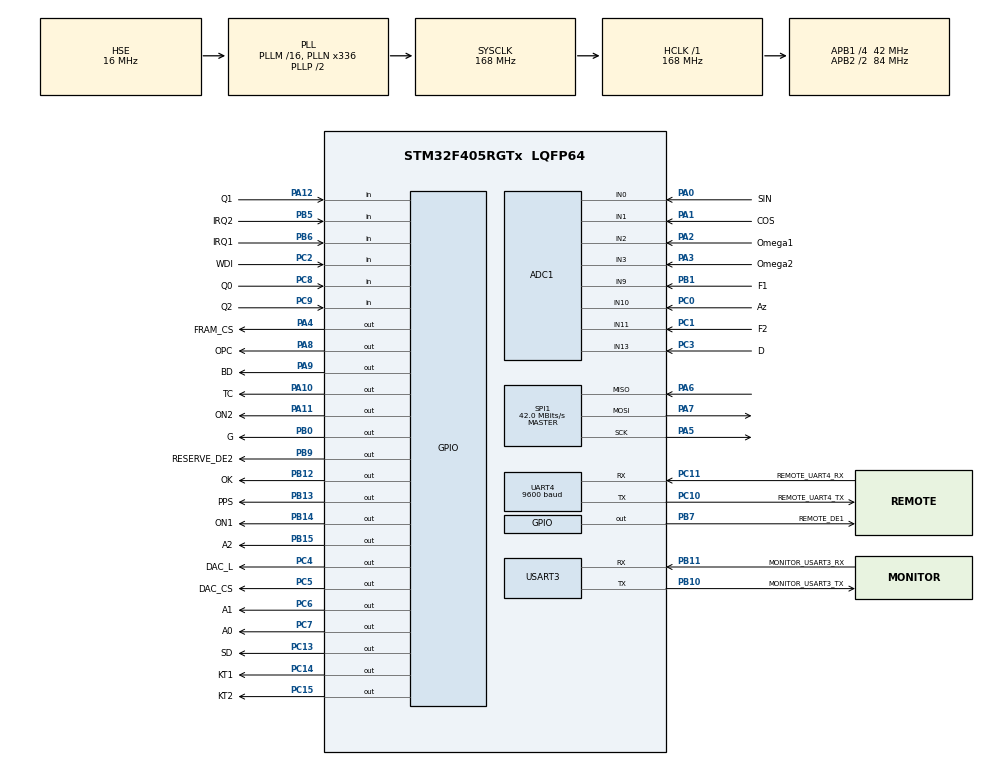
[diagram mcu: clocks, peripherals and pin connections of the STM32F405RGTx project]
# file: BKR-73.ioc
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ADC1.Channel-0\#ChannelRegularConversion=ADC_CHANNEL_0
ADC1.Channel-2\#ChannelRegularConversion=ADC_CHANNEL_1
ADC1.Channel-3\#ChannelRegularConversion=ADC_CHANNEL_2
ADC1.Channel-4\#ChannelRegularConversion=ADC_CHANNEL_3
ADC1.Channel-5\#ChannelRegularConversion=ADC_CHANNEL_9
ADC1.Channel-6\#ChannelRegularConversion=ADC_CHANNEL_10
ADC1.Channel-7\#ChannelRegularConversion=ADC_CHANNEL_11
ADC1.Channel-8\#ChannelRegularConversion=ADC_CHANNEL_13
ADC1.ClockPrescaler=ADC_CLOCK_SYNC_PCLK_DIV8
ADC1.ContinuousConvMode=ENABLE
ADC1.DMAContinuousRequests=ENABLE
ADC1.EOCSelection=ADC_EOC_SEQ_CONV
ADC1.EnableAnalogWatchDog=false
ADC1.NbrOfConversion=8
ADC1.NbrOfConversionFlag=1
ADC1.Rank-0\#ChannelRegularConversion=1
ADC1.Rank-2\#ChannelRegularConversion=2
ADC1.Rank-3\#ChannelRegularConversion=3
ADC1.Rank-4\#ChannelRegularConversion=4
ADC1.Rank-5\#ChannelRegularConversion=5
ADC1.Rank-6\#ChannelRegularConversion=6
ADC1.Rank-7\#ChannelRegularConversion=7
ADC1.Rank-8\#ChannelRegularConversion=8
ADC1.SamplingTime-0\#ChannelRegularConversion=ADC_SAMPLETIME_15CYCLES
ADC1.SamplingTime-2\#ChannelRegularConversion=ADC_SAMPLETIME_15CYCLES
ADC1.SamplingTime-3\#ChannelRegularConversion=ADC_SAMPLETIME_15CYCLES
ADC1.SamplingTime-4\#ChannelRegularConversion=ADC_SAMPLETIME_15CYCLES
ADC1.SamplingTime-5\#ChannelRegularConversion=ADC_SAMPLETIME_15CYCLES
ADC1.SamplingTime-6\#ChannelRegularConversion=ADC_SAMPLETIME_15CYCLES
ADC1.SamplingTime-7\#ChannelRegularConversion=ADC_SAMPLETIME_15CYCLES
ADC1.SamplingTime-8\#ChannelRegularConversion=ADC_SAMPLETIME_15CYCLES
ADC1.ScanConvMode=ENABLE
ADC1.master=1
Dma.ADC1.0.Direction=DMA_PERIPH_TO_MEMORY
Dma.ADC1.0.FIFOMode=DMA_FIFOMODE_DISABLE
Dma.ADC1.0.Instance=DMA2_Stream0
Dma.ADC1.0.MemDataAlignment=DMA_MDATAALIGN_HALFWORD
Dma.ADC1.0.MemInc=DMA_MINC_ENABLE
Dma.ADC1.0.Mode=DMA_CIRCULAR
Dma.ADC1.0.PeriphDataAlignment=DMA_PDATAALIGN_HALFWORD
Dma.ADC1.0.PeriphInc=DMA_PINC_DISABLE
Dma.ADC1.0.Priority=DMA_PRIORITY_LOW
Dma.Request0=ADC1
Mcu.Family=STM32F4
Mcu.Name=STM32F405RGTx
Mcu.Package=LQFP64
NVIC.ADC_IRQn=true\:0\:0\:false\:false\:true\:true\:true\:true
NVIC.DMA2_Stream0_IRQn=true\:0\:0\:false\:false\:true\:false\:true\:true
NVIC.PriorityGroup=NVIC_PRIORITYGROUP_4
PA0-WKUP.GPIO_Label=SIN
PA0-WKUP.Signal=ADCx_IN0
PA1.GPIO_Label=COS
PA1.Signal=ADCx_IN1
PA10.GPIO_Label=TC
PA10.Signal=GPIO_Output
PA11.GPIO_Label=ON2
PA11.Signal=GPIO_Output
PA12.GPIO_Label=Q1
PA12.Signal=GPIO_Input
PA13.Mode=JTAG_5_pins
PA13.Signal=SYS_JTMS-SWDIO
PA14.Mode=JTAG_5_pins
PA14.Signal=SYS_JTCK-SWCLK
PA15.Mode=JTAG_5_pins
PA15.Signal=SYS_JTDI
PA2.GPIO_Label=Omega1
PA2.Signal=ADCx_IN2
PA3.GPIO_Label=Omega2
PA3.Signal=ADCx_IN3
PA4.GPIO_Label=FRAM_CS
PA4.Signal=GPIO_Output
PA5.Mode=Full_Duplex_Master
PA5.Signal=SPI1_SCK
PA6.Mode=Full_Duplex_Master
PA6.Signal=SPI1_MISO
PA7.Mode=Full_Duplex_Master
PA7.Signal=SPI1_MOSI
PA8.GPIO_Label=OPC
PA8.Signal=GPIO_Output
PA9.GPIO_Label=BD
PA9.Signal=GPIO_Output
PB0.GPIO_Label=G
PB0.Signal=GPIO_Output
PB1.GPIO_Label=F1
PB1.Signal=ADCx_IN9
PB10.GPIO_Label=MONITOR_USART3_TX
PB10.Mode=Asynchronous
PB10.Signal=USART3_TX
PB11.GPIO_Label=MONITOR_USART3_RX
PB11.Mode=Asynchronous
PB11.Signal=USART3_RX
PB12.GPIO_Label=OK
PB12.Signal=GPIO_Output
PB13.GPIO_Label=PPS
PB13.Signal=GPIO_Output
PB14.GPIO_Label=ON1
PB14.Signal=GPIO_Output
PB15.GPIO_Label=A2
PB15.Signal=GPIO_Output
PB3.Mode=JTAG_5_pins
PB3.Signal=SYS_JTDO-SWO
PB4.Mode=JTAG_5_pins
PB4.Signal=SYS_JTRST
PB5.GPIO_Label=IRQ2
PB5.Signal=GPIO_Input
PB6.GPIO_Label=IRQ1
PB6.Signal=GPIO_Input
PB7.GPIO_Label=REMOTE_DE1
PB7.Signal=GPIO_Output
PB9.GPIO_Label=RESERVE_DE2
PB9.Signal=GPIO_Output
PC0.GPIO_Label=Az
PC0.Signal=ADCx_IN10
PC1.GPIO_Label=F2
PC1.Signal=ADCx_IN11
PC10.GPIO_Label=REMOTE_UART4_TX
PC10.Mode=Asynchronous
PC10.Signal=UART4_TX
PC11.GPIO_Label=REMOTE_UART4_RX
PC11.Mode=Asynchronous
PC11.Signal=UART4_RX
PC12.GPIO_Label=RESERVE_UART5_TX
PC12.Signal=UART5_TX
PC13-ANTI_TAMP.GPIO_Label=SD
PC13-ANTI_TAMP.Signal=GPIO_Output
PC14-OSC32_IN.GPIO_Label=KT1
PC14-OSC32_IN.Signal=GPIO_Output
PC15-OSC32_OUT.GPIO_Label=KT2
PC15-OSC32_OUT.Signal=GPIO_Output
PC2.GPIO_Label=WDI
PC2.GPIO_Mode=GPIO_MODE_INPUT
PC2.Signal=GPIO_Input
PC3.GPIO_Label=D
PC3.Signal=ADCx_IN13
PC4.GPIO_Label=DAC_L
PC4.Signal=GPIO_Output
PC5.GPIO_Label=DAC_CS
PC5.Signal=GPIO_Output
PC6.GPIO_Label=A1
PC6.Signal=GPIO_Output
PC7.GPIO_Label=A0
PC7.Signal=GPIO_Output
PC8.GPIO_Label=Q0
PC8.Signal=GPIO_Input
PC9.GPIO_Label=Q2
PC9.Signal=GPIO_Input
PD2.GPIO_Label=RESERVE_UART5_RX
PD2.Signal=UART5_RX
PH0-OSC_IN.Mode=HSE-External-Oscillator
PH0-OSC_IN.Signal=RCC_OSC_IN
PH1-OSC_OUT.Mode=HSE-External-Oscillator
PH1-OSC_OUT.Signal=RCC_OSC_OUT
ProjectManager.HeapSize=0x200
ProjectManager.StackSize=0x400
ProjectManager.TargetToolchain=STM32CubeIDE
RCC.48MHZClocksFreq_Value=84000000
RCC.AHBFreq_Value=168000000
RCC.APB1CLKDivider=RCC_HCLK_DIV4
RCC.APB1Freq_Value=42000000
RCC.APB1TimFreq_Value=84000000
RCC.APB2CLKDivider=RCC_HCLK_DIV2
RCC.APB2Freq_Value=84000000
RCC.APB2TimFreq_Value=168000000
RCC.CortexFreq_Value=168000000
RCC.HCLKFreq_Value=168000000
RCC.HSE_VALUE=16000000
RCC.HSI_VALUE=16000000
RCC.LSE_VALUE=32768
RCC.PLLN=336
RCC.PLLSourceVirtual=RCC_PLLSOURCE_HSE
RCC.SYSCLKFreq_VALUE=168000000
RCC.SYSCLKSource=RCC_SYSCLKSOURCE_PLLCLK
RCC.VCOOutputFreq_Value=336000000
SH.ADCx_IN0.0=ADC1_IN0,IN0
SH.ADCx_IN1.0=ADC1_IN1,IN1
SH.ADCx_IN10.0=ADC1_IN10,IN10
SH.ADCx_IN11.0=ADC1_IN11,IN11
SH.ADCx_IN13.0=ADC1_IN13,IN13
SH.ADCx_IN2.0=ADC1_IN2,IN2
SH.ADCx_IN3.0=ADC1_IN3,IN3
SH.ADCx_IN9.0=ADC1_IN9,IN9
SPI1.BaudRatePrescaler=SPI_BAUDRATEPRESCALER_2
SPI1.CalculateBaudRate=42.0 MBits/s
SPI1.Direction=SPI_DIRECTION_2LINES
SPI1.Mode=SPI_MODE_MASTER
SPI1.VirtualType=VM_MASTER
TIM1.Period=49
TIM1.Prescaler=839
TIM1.TIM_MasterSlaveMode=TIM_MASTERSLAVEMODE_ENABLE
TIM2.Period=99
TIM2.Prescaler=8399
TIM2.TIM_MasterSlaveMode=TIM_MASTERSLAVEMODE_ENABLE
UART4.BaudRate=9600
UART4.OverSampling=UART_OVERSAMPLING_16
UART4.Parity=PARITY_EVEN
UART4.VirtualMode=Asynchronous
USART3.VirtualMode=VM_ASYNC
VP_TIM1_VS_ClockSourceITR.Mode=TriggerSource_ITR0
VP_TIM2_VS_ClockSourceITR.Mode=TriggerSource_ITR0
VP_TIM2_VS_ControllerModeTrigger.Mode=Trigger Mode
board=custom

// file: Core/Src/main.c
/* USER CODE BEGIN Header */
/**
  ******************************************************************************
  * @file           : main.c
  * @brief          : Main program body
  ******************************************************************************
  * @attention
  *
  * Copyright (c) 2024 STMicroelectronics.
  * All rights reserved.
  *
  * This software is licensed under terms that can be found in the LICENSE file
  * in the root directory of this software component.
  * If no LICENSE file comes with this software, it is provided AS-IS.
  *
  ******************************************************************************
  */
/* USER CODE END Header */
#include "main.h"

/* USER CODE BEGIN Includes */
#include "dispatcher.h"
/* USER CODE END Includes */

ADC_HandleTypeDef hadc1;
DMA_HandleTypeDef hdma_adc1;

SPI_HandleTypeDef hspi1;

TIM_HandleTypeDef htim1;
TIM_HandleTypeDef htim2;

UART_HandleTypeDef huart4;
UART_HandleTypeDef huart3;

void SystemClock_Config(void);
static void MX_GPIO_Init(void);
static void MX_DMA_Init(void);
static void MX_ADC1_Init(void);
static void MX_SPI1_Init(void);
static void MX_UART4_Init(void);
static void MX_USART3_UART_Init(void);
static void MX_TIM2_Init(void);
static void MX_TIM1_Init(void);

/* USER CODE BEGIN 0 */
ACD_t adcData;
/* USER CODE END 0 */

int main(void)
{

  /* MCU Configuration--------------------------------------------------------*/

  /* Reset of all peripherals, Initializes the Flash interface and the Systick. */
  HAL_Init();

  /* Configure the system clock */
  SystemClock_Config();

  /* Initialize all configured peripherals */
  MX_GPIO_Init();
  MX_DMA_Init();
  MX_ADC1_Init();
  MX_SPI1_Init();
  MX_UART4_Init();
  MX_USART3_UART_Init();
  MX_TIM2_Init();
  MX_TIM1_Init();

  /* Infinite loop */
  /* USER CODE BEGIN WHILE */
  while (1)
  {

      // State machine entry & exit point
      //===========================================================
      (*Dispatcher_Thread_Ptr)();   // jump to a state (A0,B0,...)
      //===========================================================

    /* USER CODE END WHILE */

  }
}

void SystemClock_Config(void)
{
  RCC_OscInitTypeDef RCC_OscInitStruct = {0};
  RCC_ClkInitTypeDef RCC_ClkInitStruct = {0};

  /** Configure the main internal regulator output voltage
  */
  __HAL_RCC_PWR_CLK_ENABLE();
  __HAL_PWR_VOLTAGESCALING_CONFIG(PWR_REGULATOR_VOLTAGE_SCALE1);

  /** Initializes the RCC Oscillators according to the specified parameters
  * in the RCC_OscInitTypeDef structure.
  */
  RCC_OscInitStruct.OscillatorType = RCC_OSCILLATORTYPE_HSE;
  RCC_OscInitStruct.HSEState = RCC_HSE_ON;
  RCC_OscInitStruct.PLL.PLLState = RCC_PLL_ON;
  RCC_OscInitStruct.PLL.PLLSource = RCC_PLLSOURCE_HSE;
  RCC_OscInitStruct.PLL.PLLM = 16;
  RCC_OscInitStruct.PLL.PLLN = 336;
  RCC_OscInitStruct.PLL.PLLP = RCC_PLLP_DIV2;
  RCC_OscInitStruct.PLL.PLLQ = 4;
  if (HAL_RCC_OscConfig(&RCC_OscInitStruct) != HAL_OK)
  {
    Error_Handler();
  }

  /** Initializes the CPU, AHB and APB buses clocks
  */
  RCC_ClkInitStruct.ClockType = RCC_CLOCKTYPE_HCLK|RCC_CLOCKTYPE_SYSCLK
                              |RCC_CLOCKTYPE_PCLK1|RCC_CLOCKTYPE_PCLK2;
  RCC_ClkInitStruct.SYSCLKSource = RCC_SYSCLKSOURCE_PLLCLK;
  RCC_ClkInitStruct.AHBCLKDivider = RCC_SYSCLK_DIV1;
  RCC_ClkInitStruct.APB1CLKDivider = RCC_HCLK_DIV4;
  RCC_ClkInitStruct.APB2CLKDivider = RCC_HCLK_DIV2;

  if (HAL_RCC_ClockConfig(&RCC_ClkInitStruct, FLASH_LATENCY_5) != HAL_OK)
  {
    Error_Handler();
  }
}

static void MX_ADC1_Init(void)
{

  ADC_ChannelConfTypeDef sConfig = {0};

  /** Configure the global features of the ADC (Clock, Resolution, Data Alignment and number of conversion)
  */
  hadc1.Instance = ADC1;
  hadc1.Init.ClockPrescaler = ADC_CLOCK_SYNC_PCLK_DIV8;
  hadc1.Init.Resolution = ADC_RESOLUTION_12B;
  hadc1.Init.ScanConvMode = ENABLE;
  hadc1.Init.ContinuousConvMode = ENABLE;
  hadc1.Init.DiscontinuousConvMode = DISABLE;
  hadc1.Init.ExternalTrigConvEdge = ADC_EXTERNALTRIGCONVEDGE_NONE;
  hadc1.Init.ExternalTrigConv = ADC_SOFTWARE_START;
  hadc1.Init.DataAlign = ADC_DATAALIGN_RIGHT;
  hadc1.Init.NbrOfConversion = 8;
  hadc1.Init.DMAContinuousRequests = ENABLE;
  hadc1.Init.EOCSelection = ADC_EOC_SEQ_CONV;
  if (HAL_ADC_Init(&hadc1) != HAL_OK)
  {
    Error_Handler();
  }

  /** Configure for the selected ADC regular channel its corresponding rank in the sequencer and its sample time.
  */
  sConfig.Channel = ADC_CHANNEL_0;
  sConfig.Rank = 1;
  sConfig.SamplingTime = ADC_SAMPLETIME_15CYCLES;
  if (HAL_ADC_ConfigChannel(&hadc1, &sConfig) != HAL_OK)
  {
    Error_Handler();
  }

  /** Configure for the selected ADC regular channel its corresponding rank in the sequencer and its sample time.
  */
  sConfig.Channel = ADC_CHANNEL_1;
  sConfig.Rank = 2;
  if (HAL_ADC_ConfigChannel(&hadc1, &sConfig) != HAL_OK)
  {
    Error_Handler();
  }

  /** Configure for the selected ADC regular channel its corresponding rank in the sequencer and its sample time.
  */
  sConfig.Channel = ADC_CHANNEL_2;
  sConfig.Rank = 3;
  if (HAL_ADC_ConfigChannel(&hadc1, &sConfig) != HAL_OK)
  {
    Error_Handler();
  }

  /** Configure for the selected ADC regular channel its corresponding rank in the sequencer and its sample time.
  */
  sConfig.Channel = ADC_CHANNEL_3;
  sConfig.Rank = 4;
  if (HAL_ADC_ConfigChannel(&hadc1, &sConfig) != HAL_OK)
  {
    Error_Handler();
  }

  /** Configure for the selected ADC regular channel its corresponding rank in the sequencer and its sample time.
  */
  sConfig.Channel = ADC_CHANNEL_9;
  sConfig.Rank = 5;
  if (HAL_ADC_ConfigChannel(&hadc1, &sConfig) != HAL_OK)
  {
    Error_Handler();
  }

  /** Configure for the selected ADC regular channel its corresponding rank in the sequencer and its sample time.
  */
  sConfig.Channel = ADC_CHANNEL_10;
  sConfig.Rank = 6;
  if (HAL_ADC_ConfigChannel(&hadc1, &sConfig) != HAL_OK)
  {
    Error_Handler();
  }

  /** Configure for the selected ADC regular channel its corresponding rank in the sequencer and its sample time.
  */
  sConfig.Channel = ADC_CHANNEL_11;
  sConfig.Rank = 7;
  if (HAL_ADC_ConfigChannel(&hadc1, &sConfig) != HAL_OK)
  {
    Error_Handler();
  }

  /** Configure for the selected ADC regular channel its corresponding rank in the sequencer and its sample time.
  */
  sConfig.Channel = ADC_CHANNEL_13;
  sConfig.Rank = 8;
  if (HAL_ADC_ConfigChannel(&hadc1, &sConfig) != HAL_OK)
  {
    Error_Handler();
  }
  /* USER CODE BEGIN ADC1_Init 2 */
  HAL_ADC_Start_DMA(&hadc1, (uint32_t*)&adcData, NUM_CHANNELS);
  /* USER CODE END ADC1_Init 2 */

}

static void MX_SPI1_Init(void)
{

  /* SPI1 parameter configuration*/
  hspi1.Instance = SPI1;
  hspi1.Init.Mode = SPI_MODE_MASTER;
  hspi1.Init.Direction = SPI_DIRECTION_2LINES;
  hspi1.Init.DataSize = SPI_DATASIZE_8BIT;
  hspi1.Init.CLKPolarity = SPI_POLARITY_LOW;
  hspi1.Init.CLKPhase = SPI_PHASE_1EDGE;
  hspi1.Init.NSS = SPI_NSS_SOFT;
  hspi1.Init.BaudRatePrescaler = SPI_BAUDRATEPRESCALER_2;
  hspi1.Init.FirstBit = SPI_FIRSTBIT_MSB;
  hspi1.Init.TIMode = SPI_TIMODE_DISABLE;
  hspi1.Init.CRCCalculation = SPI_CRCCALCULATION_DISABLE;
  hspi1.Init.CRCPolynomial = 10;
  if (HAL_SPI_Init(&hspi1) != HAL_OK)
  {
    Error_Handler();
  }

}

static void MX_TIM1_Init(void)
{

  TIM_SlaveConfigTypeDef sSlaveConfig = {0};
  TIM_MasterConfigTypeDef sMasterConfig = {0};

  htim1.Instance = TIM1;
  htim1.Init.Prescaler = 839;
  htim1.Init.CounterMode = TIM_COUNTERMODE_UP;
  htim1.Init.Period = 49;
  htim1.Init.ClockDivision = TIM_CLOCKDIVISION_DIV1;
  htim1.Init.RepetitionCounter = 0;
  htim1.Init.AutoReloadPreload = TIM_AUTORELOAD_PRELOAD_DISABLE;
  if (HAL_TIM_Base_Init(&htim1) != HAL_OK)
  {
    Error_Handler();
  }
  sSlaveConfig.SlaveMode = TIM_SLAVEMODE_DISABLE;
  sSlaveConfig.InputTrigger = TIM_TS_ITR0;
  if (HAL_TIM_SlaveConfigSynchro(&htim1, &sSlaveConfig) != HAL_OK)
  {
    Error_Handler();
  }
  sMasterConfig.MasterOutputTrigger = TIM_TRGO_RESET;
  sMasterConfig.MasterSlaveMode = TIM_MASTERSLAVEMODE_ENABLE;
  if (HAL_TIMEx_MasterConfigSynchronization(&htim1, &sMasterConfig) != HAL_OK)
  {
    Error_Handler();
  }
  /* USER CODE BEGIN TIM1_Init 2 */
  HAL_TIM_Base_Start(&htim1);
  /* USER CODE END TIM1_Init 2 */

}

static void MX_TIM2_Init(void)
{

  TIM_SlaveConfigTypeDef sSlaveConfig = {0};
  TIM_MasterConfigTypeDef sMasterConfig = {0};

  htim2.Instance = TIM2;
  htim2.Init.Prescaler = 8399;
  htim2.Init.CounterMode = TIM_COUNTERMODE_UP;
  htim2.Init.Period = 99;
  htim2.Init.ClockDivision = TIM_CLOCKDIVISION_DIV1;
  htim2.Init.AutoReloadPreload = TIM_AUTORELOAD_PRELOAD_DISABLE;
  if (HAL_TIM_Base_Init(&htim2) != HAL_OK)
  {
    Error_Handler();
  }
  sSlaveConfig.SlaveMode = TIM_SLAVEMODE_TRIGGER;
  sSlaveConfig.InputTrigger = TIM_TS_ITR0;
  if (HAL_TIM_SlaveConfigSynchro(&htim2, &sSlaveConfig) != HAL_OK)
  {
    Error_Handler();
  }
  sMasterConfig.MasterOutputTrigger = TIM_TRGO_RESET;
  sMasterConfig.MasterSlaveMode = TIM_MASTERSLAVEMODE_ENABLE;
  if (HAL_TIMEx_MasterConfigSynchronization(&htim2, &sMasterConfig) != HAL_OK)
  {
    Error_Handler();
  }
  /* USER CODE BEGIN TIM2_Init 2 */
  //LL_TIM_EnableCounter(TIM2);
  /* USER CODE END TIM2_Init 2 */

}

static void MX_UART4_Init(void)
{

  huart4.Instance = UART4;
  huart4.Init.BaudRate = 9600;
  huart4.Init.WordLength = UART_WORDLENGTH_8B;
  huart4.Init.StopBits = UART_STOPBITS_1;
  huart4.Init.Parity = UART_PARITY_EVEN;
  huart4.Init.Mode = UART_MODE_TX_RX;
  huart4.Init.HwFlowCtl = UART_HWCONTROL_NONE;
  huart4.Init.OverSampling = UART_OVERSAMPLING_16;
  if (HAL_UART_Init(&huart4) != HAL_OK)
  {
    Error_Handler();
  }

}

static void MX_USART3_UART_Init(void)
{

  huart3.Instance = USART3;
  huart3.Init.BaudRate = 115200;
  huart3.Init.WordLength = UART_WORDLENGTH_8B;
  huart3.Init.StopBits = UART_STOPBITS_1;
  huart3.Init.Parity = UART_PARITY_NONE;
  huart3.Init.Mode = UART_MODE_TX_RX;
  huart3.Init.HwFlowCtl = UART_HWCONTROL_NONE;
  huart3.Init.OverSampling = UART_OVERSAMPLING_16;
  if (HAL_UART_Init(&huart3) != HAL_OK)
  {
    Error_Handler();
  }

}

static void MX_DMA_Init(void)
{

  /* DMA controller clock enable */
  __HAL_RCC_DMA2_CLK_ENABLE();

  /* DMA interrupt init */
  /* DMA2_Stream0_IRQn interrupt configuration */
  HAL_NVIC_SetPriority(DMA2_Stream0_IRQn, 0, 0);
  HAL_NVIC_EnableIRQ(DMA2_Stream0_IRQn);

}

static void MX_GPIO_Init(void)
{
  GPIO_InitTypeDef GPIO_InitStruct = {0};

  /* GPIO Ports Clock Enable */
  __HAL_RCC_GPIOC_CLK_ENABLE();
  __HAL_RCC_GPIOH_CLK_ENABLE();
  __HAL_RCC_GPIOA_CLK_ENABLE();
  __HAL_RCC_GPIOB_CLK_ENABLE();
  __HAL_RCC_GPIOD_CLK_ENABLE();

  /*Configure GPIO pin Output Level */
  HAL_GPIO_WritePin(GPIOC, SD_Pin|KT1_Pin|KT2_Pin|DAC_L_Pin
                          |DAC_CS_Pin|A1_Pin|A0_Pin, GPIO_PIN_RESET);

  /*Configure GPIO pin Output Level */
  HAL_GPIO_WritePin(GPIOA, FRAM_CS_Pin|OPC_Pin|BD_Pin|TC_Pin
                          |ON2_Pin, GPIO_PIN_RESET);

  /*Configure GPIO pin Output Level */
  HAL_GPIO_WritePin(GPIOB, G_Pin|OK_Pin|PPS_Pin|ON1_Pin
                          |A2_Pin|REMOTE_DE1_Pin|RESERVE_DE2_Pin, GPIO_PIN_RESET);

  /*Configure GPIO pins : SD_Pin KT1_Pin KT2_Pin DAC_L_Pin
                           DAC_CS_Pin A1_Pin A0_Pin */
  GPIO_InitStruct.Pin = SD_Pin|KT1_Pin|KT2_Pin|DAC_L_Pin
                          |DAC_CS_Pin|A1_Pin|A0_Pin;
  GPIO_InitStruct.Mode = GPIO_MODE_OUTPUT_PP;
  GPIO_InitStruct.Pull = GPIO_NOPULL;
  GPIO_InitStruct.Speed = GPIO_SPEED_FREQ_LOW;
  HAL_GPIO_Init(GPIOC, &GPIO_InitStruct);

  /*Configure GPIO pins : WDI_Pin Q0_Pin Q2_Pin */
  GPIO_InitStruct.Pin = WDI_Pin|Q0_Pin|Q2_Pin;
  GPIO_InitStruct.Mode = GPIO_MODE_INPUT;
  GPIO_InitStruct.Pull = GPIO_NOPULL;
  HAL_GPIO_Init(GPIOC, &GPIO_InitStruct);

  /*Configure GPIO pins : FRAM_CS_Pin OPC_Pin BD_Pin TC_Pin
                           ON2_Pin */
  GPIO_InitStruct.Pin = FRAM_CS_Pin|OPC_Pin|BD_Pin|TC_Pin
                          |ON2_Pin;
  GPIO_InitStruct.Mode = GPIO_MODE_OUTPUT_PP;
  GPIO_InitStruct.Pull = GPIO_NOPULL;
  GPIO_InitStruct.Speed = GPIO_SPEED_FREQ_LOW;
  HAL_GPIO_Init(GPIOA, &GPIO_InitStruct);

  /*Configure GPIO pins : G_Pin OK_Pin PPS_Pin ON1_Pin
                           A2_Pin REMOTE_DE1_Pin RESERVE_DE2_Pin */
  GPIO_InitStruct.Pin = G_Pin|OK_Pin|PPS_Pin|ON1_Pin
                          |A2_Pin|REMOTE_DE1_Pin|RESERVE_DE2_Pin;
  GPIO_InitStruct.Mode = GPIO_MODE_OUTPUT_PP;
  GPIO_InitStruct.Pull = GPIO_NOPULL;
  GPIO_InitStruct.Speed = GPIO_SPEED_FREQ_LOW;
  HAL_GPIO_Init(GPIOB, &GPIO_InitStruct);

  /*Configure GPIO pin : Q1_Pin */
  GPIO_InitStruct.Pin = Q1_Pin;
  GPIO_InitStruct.Mode = GPIO_MODE_INPUT;
  GPIO_InitStruct.Pull = GPIO_NOPULL;
  HAL_GPIO_Init(Q1_GPIO_Port, &GPIO_InitStruct);

  /*Configure GPIO pin : RESERVE_UART5_TX_Pin */
  GPIO_InitStruct.Pin = RESERVE_UART5_TX_Pin;
  GPIO_InitStruct.Mode = GPIO_MODE_AF_PP;
  GPIO_InitStruct.Pull = GPIO_NOPULL;
  GPIO_InitStruct.Speed = GPIO_SPEED_FREQ_VERY_HIGH;
  GPIO_InitStruct.Alternate = GPIO_AF8_UART5;
  HAL_GPIO_Init(RESERVE_UART5_TX_GPIO_Port, &GPIO_InitStruct);

  /*Configure GPIO pin : RESERVE_UART5_RX_Pin */
  GPIO_InitStruct.Pin = RESERVE_UART5_RX_Pin;
  GPIO_InitStruct.Mode = GPIO_MODE_AF_PP;
  GPIO_InitStruct.Pull = GPIO_NOPULL;
  GPIO_InitStruct.Speed = GPIO_SPEED_FREQ_VERY_HIGH;
  GPIO_InitStruct.Alternate = GPIO_AF8_UART5;
  HAL_GPIO_Init(RESERVE_UART5_RX_GPIO_Port, &GPIO_InitStruct);

  /*Configure GPIO pins : IRQ2_Pin IRQ1_Pin */
  GPIO_InitStruct.Pin = IRQ2_Pin|IRQ1_Pin;
  GPIO_InitStruct.Mode = GPIO_MODE_INPUT;
  GPIO_InitStruct.Pull = GPIO_NOPULL;
  HAL_GPIO_Init(GPIOB, &GPIO_InitStruct);

}

void Error_Handler(void)
{
  __disable_irq();
  while (1)
  {
  }
}
